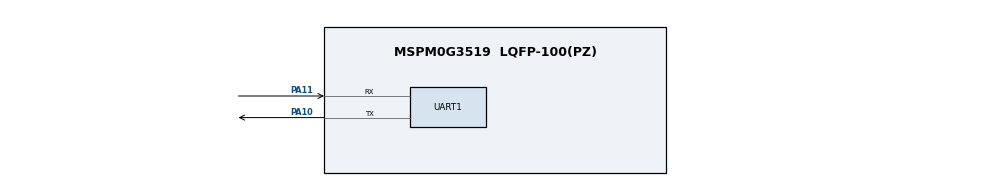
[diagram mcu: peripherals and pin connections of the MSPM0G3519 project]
// @cliArgs --device "MSPM0G351X" --package "LQFP-100(PZ)" --part "Default"
// @v2CliArgs --device "MSPM0G3519" --package "LQFP-100(PZ)"
// @cliArgs --board /ti/boards/LP_MSPM0G3519 --rtos nortos

const UART  = scripting.addModule("/ti/driverlib/UART", {}, false);
const UART1 = UART.addInstance();

const Board                       = scripting.addModule("/ti/driverlib/Board", {}, false);
Board.configureUnused             = false;

const SYSCTL                 = scripting.addModule("/ti/driverlib/SYSCTL", {}, false);

UART1.$name                    = "UART_0";
UART1.targetBaudRate           = 115200;
UART1.enableInternalLoopback   = false;
UART1.enabledInterrupts        = [];
UART1.peripheral.$assign       = "UART0";
UART1.peripheral.rxPin.$assign = "PA11";
UART1.peripheral.txPin.$assign = "PA10";

const ProjectConfig              = scripting.addModule("/ti/project_config/ProjectConfig", {}, false);
